# ADSP-2183xW_HPC register map
Vendor: Analog Devices; Series: ADSP-2183xW_HPC; File version: 3.0.3.517
CPU: 
Registers are 32-bit, read-write, reset 0x0 unless marked. A register's access mark holds for its fields unless they carry their own. Offsets are from the block's base; [hi:lo] are bit positions; {n}, {i} and the like mark numbered series; 'fields as' and 'values as' point back to an identical list.

## Trax_Registers
Base 0x31114000
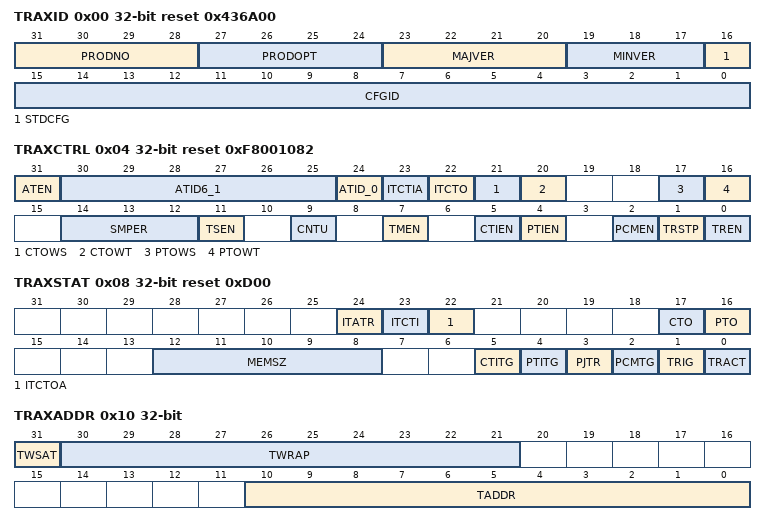
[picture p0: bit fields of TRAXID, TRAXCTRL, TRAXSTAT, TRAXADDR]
0x00 TRAXID reset 0x436A00
  [31:28] PRODNO ro, [27:24] PRODOPT ro, [23:20] MAJVER ro, [19:17] MINVER ro, [16] STDCFG ro, [15:0] CFGID ro
0x04 TRAXCTRL reset 0xF8001082
  [31] ATEN range 0x00000000..0x00000001
  [30:25] ATID6_1 range 0x00000000..0x0000003F
  [24] ATID_0 range 0x00000000..0x00000001
  [23] ITCTIA range 0x00000000..0x00000001
  [22] ITCTO range 0x00000000..0x00000001
  [21] CTOWS range 0x00000000..0x00000001
  [20] CTOWT range 0x00000000..0x00000001
  [17] PTOWS range 0x00000000..0x00000001
  [16] PTOWT range 0x00000000..0x00000001
  [14:12] SMPER
    0=SMNone; 1=SMPER256; 2=SMPER128; 3=SMPER64; 4=SMPER32; 5=SMPER16; 6=SMPER8
  [11] TSEN range 0x00000000..0x00000001
  [9] CNTU range 0x00000000..0x00000001
  [7] TMEN range 0x00000000..0x00000001
  [5] CTIEN range 0x00000000..0x00000001
  [4] PTIEN range 0x00000000..0x00000001
  [2] PCMEN range 0x00000000..0x00000001
  [1] TRSTP range 0x00000000..0x00000001
  [0] TREN range 0x00000000..0x00000001
0x08 TRAXSTAT reset 0xD00
  [24] ITATR ro, [23] ITCTI ro, [22] ITCTOA ro, [17] CTO ro, [16] PTO ro, [12:8] MEMSZ ro, [5] CTITG ro, [4] PTITG ro, [3] PJTR ro, [2] PCMTG ro, [1] TRIG ro, [0] TRACT ro
0x0C TRAXDATA
  [31:0] TRAXDATA range 0x00000000..0xFFFFFFFF
0x10 TRAXADDR
  [31] TWSAT range 0x00000000..0x00000001, [30:21] TWRAP range 0x00000000..0x000003FF, [10:0] TADDR range 0x00000000..0x000007FF
0x14 TRIGGERPC
  [31:0] TRIGGERPC range 0x00000000..0xFFFFFFFF
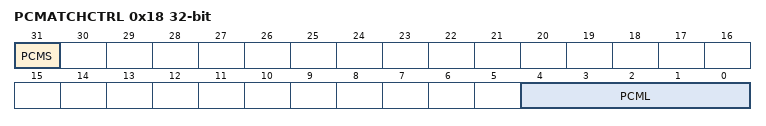
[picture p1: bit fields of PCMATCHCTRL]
0x18 PCMATCHCTRL
  [31] PCMS range 0x00000000..0x00000001, [4:0] PCML range 0x00000000..0x0000001F
0x1C DELAYCNT
  [23:0] DELAYCNT range 0x00000000..0x00FFFFFF
0x20 MEMADDRSTART
  [10:0] MEMADDRSTART range 0x00000000..0x000007FF
0x24 MEMADDREND reset 0x7FF
  [10:0] MEMADDREND range 0x00000000..0x000007FF
0x40 EXTTIMELO
  [31:0] EXTTIMELO ro
0x44 EXTTIMEHI
  [31:0] EXTTIMEHI ro

## Performance_Monitor_Registers
Base 0x31114000
0x1000 PMG
  [0] PMEN range 0x00000000..0x00000001
0x1010 INTPC
  [31:0] INTPC ro
{0x1080+4i} PM{i} (i=0..7)
  [31:0] PM{i} range 0x00000000..0xFFFFFFFF
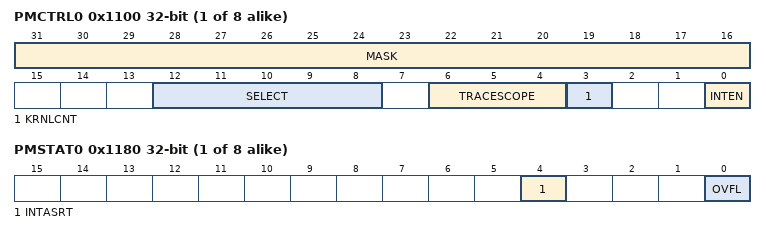
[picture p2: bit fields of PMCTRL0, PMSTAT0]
{0x1100+4i} PMCTRL{i} (i=0..7)
  [31:16] MASK range 0x00000000..0x0000FFFF, [12:8] SELECT range 0x00000000..0x0000001F, [6:4] TRACESCOPE range 0x00000000..0x00000007, [3] KRNLCNT range 0x00000000..0x00000001, [0] INTEN range 0x00000000..0x00000001
{0x1180+4i} PMSTAT{i} (i=0..7)
  [4] INTASRT range 0x00000000..0x00000001, [0] OVFL range 0x00000000..0x00000001

## OCD_Registers
Base 0x31114000
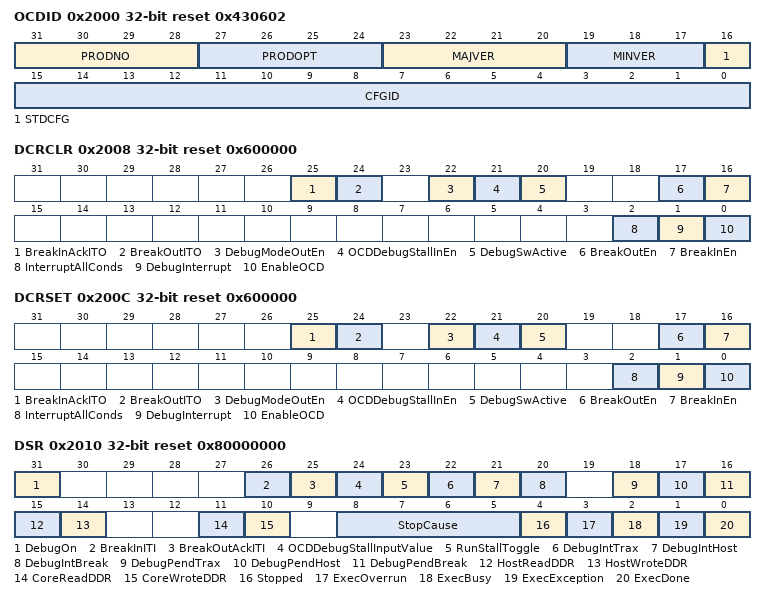
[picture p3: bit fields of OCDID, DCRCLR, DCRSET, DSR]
0x2000 OCDID reset 0x430602
  [31:28] PRODNO ro, [27:24] PRODOPT ro, [23:20] MAJVER ro, [19:17] MINVER ro, [16] STDCFG ro, [15:0] CFGID ro
0x2008 DCRCLR reset 0x600000
  [25] BreakInAckITO range 0x00000000..0x00000001, [24] BreakOutITO range 0x00000000..0x00000001, [22] DebugModeOutEn range 0x00000000..0x00000001, [21] OCDDebugStallInEn range 0x00000000..0x00000001, [20] DebugSwActive range 0x00000000..0x00000001, [17] BreakOutEn range 0x00000000..0x00000001, [16] BreakInEn range 0x00000000..0x00000001, [2] InterruptAllConds range 0x00000000..0x00000001, [1] DebugInterrupt range 0x00000000..0x00000001, [0] EnableOCD range 0x00000000..0x00000001
0x200C DCRSET reset 0x600000
  fields as DCRCLR
0x2010 DSR reset 0x80000000
  [31] DebugOn ro, [26] BreakInITI ro, [25] BreakOutAckITI ro, [24] OCDDebugStallInputValue ro, [23] RunStallToggle range 0x00000000..0x00000001, [22] DebugIntTrax range 0x00000000..0x00000001, [21] DebugIntHost range 0x00000000..0x00000001, [20] DebugIntBreak range 0x00000000..0x00000001, [18] DebugPendTrax range 0x00000000..0x00000001, [17] DebugPendHost range 0x00000000..0x00000001, [16] DebugPendBreak range 0x00000000..0x00000001, [15] HostReadDDR range 0x00000000..0x00000001, [14] HostWroteDDR range 0x00000000..0x00000001, [11] CoreReadDDR range 0x00000000..0x00000001, [10] CoreWroteDDR range 0x00000000..0x00000001, [8:5] StopCause ro, [4] Stopped ro, [3] ExecOverrun range 0x00000000..0x00000001, [2] ExecBusy ro, [1] ExecException range 0x00000000..0x00000001, [0] ExecDone range 0x00000000..0x00000001
0x2014 DDR
  [31:0] DDR range 0x00000000..0xFFFFFFFF
0x2018 DDREXEC
  [31:0] DDREXEC range 0x00000000..0xFFFFFFFF
0x201C DIR0EXEC
  [31:0] DIR0EXEC range 0x00000000..0xFFFFFFFF
{0x2020+4i} DIR{i} (i=0..3)
  [31:0] DIR{i} range 0x00000000..0xFFFFFFFF
